# H616 register map
Vendor: Allwinner; Series: H616; File version: 0.1
CPU: other 0, little endian, MPU, no FPU, 0 interrupt priority bits
Registers are 32-bit, read-write, reset 0x0 unless marked. A register's access mark holds for its fields unless they carry their own. Offsets are from the block's base; [hi:lo] are bit positions; 'fields as' and 'values as' point back to an identical list; <NAME> marks a mode.

## SPI0
Base 0x05010000
Same registers: SPI1 0x05011000
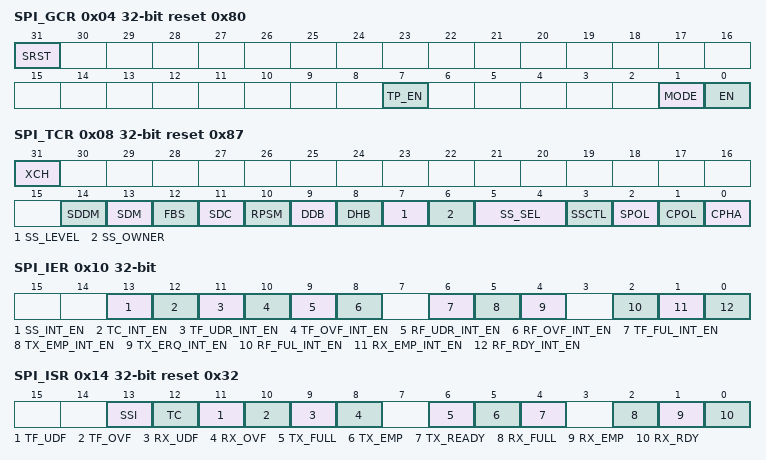
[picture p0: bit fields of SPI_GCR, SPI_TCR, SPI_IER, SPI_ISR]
0x04 SPI_GCR reset 0x80 — SPI Global Control Register
  [31] SRST — Soft reset Writing `1` to this bit will clear the SPI controller, and auto clear to `0` when reset operation completes. Writing `0` has no effect.
  [7] TP_EN — Transmit Pause Enable In master mode, it is used to control transmit state machine to stop smart burst sending when RX FIFO is full. 0: Normal operation, ignore RXFIFO status 1: Stop transmit data when RXFIFO full Cannot be written when XCH=1
    0=Normal operation, ignore RXFIFO status; 1=Stop transmit data when RXFIFO full Cannot be written when XCH=1
  [1] MODE — SPI Function Mode Select 0: Slave mode 1: Master mode Cannot be written when XCH=1
    0=Slave_mode; 1=Master mode Cannot be written when XCH=1
  [0] EN — SPI Module Enable Control 0: Disable 1: Enable After transforming from bit_mode to byte_mode, it must enable the SPI module again.
    0=Disable; 1=Enable After transforming from bit_mode to byte_mode, it must enable the SPI module again
0x08 SPI_TCR reset 0x87 — SPI Transfer Control Register
  [31] XCH — Exchange Burst In master mode it is used to start SPI burst 0: Idle 1: Initiates exchange. Writing `1` to this bit will start the SPI burst, and will auto clear after finishing the bursts transfer specified by BC. Writing `1` to SRST will also clear this bit. Writing `0` to this bit has no effect. Cannot be written when XCH=1.
    0=Idle; 1=Initiates exchange. Writing `1` to this bit will start the SPI burst, and will auto clear after finishing the bursts transfer specified by BC. Writing `1` to SRST will also clear this bit. Writing `0` to this bit has no effect. Cannot be written when XCH=1.
  [14] SDDM — Sending Data Delay Mode 0:Normal sending 1:Delay sending Set the bit to "1" to make the data that should be sent with a delay of half cycle of SPI_CLK in dual IO mode for SPI mode 0. Cannot be written when XCH=1.
  [13] SDM — Master Sample Data Mode 0: Delay sample mode 1: Normal sample mode In normal sample mode, SPI master samples the data at the correct edge for each SPI mode; In delay sample mode, SPI master samples data at the edge that is half cycle delayed by the correct edge defined in respective SPI mode. Cannot be written when XCH=1.
    0=Delay sample mode; 1=Normal sample mode In normal sample mode, SPI master samples the data at the correct edge for each SPI mode; In delay sample mode, SPI master samples data at the edge that is half cycle delayed by the correct edge defined in respective SPI mode. Cannot be written when XCH=1.
  [12] FBS — First Transmit Bit Select 0: MSB first 1: LSB first Cannot be written when XCH=1.
    0=MSB (MSB first); 1=LSB (LSB first Cannot be written when XCH=1.)
  [11] SDC — Master Sample Data Control Set this bit to `1` to make the internal read sample point with a delay of half cycle of SPI_CLK. It is used in high speed read operation to reduce the error caused by the time delay of SPI_CLK propagating between master and slave. 0: Normal operation, do not delay internal read sample point 1: Delay internal read sample point Cannot be written when XCH=1.
    0=Normal operation, do not delay internal read sample point; 1=Delay internal read sample point Cannot be written when XCH=1
  [10] RPSM — Rapids Mode Select Select rapid mode for high speed write. 0: Normal write mode 1: Rapid write mode Cannot be written when XCH=1.
    0=Normal write mode; 1=Rapid write mode Cannot be written when XCH=1
  [9] DDB — Dummy Burst Type 0: The bit value of dummy SPI burst is zero 1: The bit value of dummy SPI burst is one Cannot be written when XCH=1.
    0=zero (The bit value of dummy SPI burst is zero); 1=one (The bit value of dummy SPI burst is one Cannot be written when XCH=1.)
  [8] DHB — Discard Hash Burst In master mode it controls whether discarding unused SPI bursts 0: Receiving all SPI bursts in BC period 1: Discard unused SPI bursts, only fetching the SPI bursts during dummy burst period. The bursts number is specified by TC. Cannot be written when XCH=1.
    0=Receiving all SPI bursts in BC period; 1=Discard unused SPI bursts, only fetching the SPI bursts during dummy burst period. The bursts number is specified by TC. Cannot be written when XCH=1.
  [7] SS_LEVEL — When control SS signal manually (SPI_CTRL_REG.SS_CTRL==1), set this bit to `1` or `0` to control the level of SS signal. 0: set SS to low 1: set SS to high Cannot be written when XCH=1.
    0=set_SS_to_low; 1=set SS to high Cannot be written when XCH=1
  [6] SS_OWNER — SS Output Owner Select Usually, controller sends SS signal automatically with data together. When this bit is set to 1, software must manually write SPI_CTL_REG.SS_LEVEL to 1 or 0 to control the level of SS signal. 0: SPI controller 1: Software Cannot be written when XCH=1.
    0=SPI (SPI controller); 1=Software Cannot be written when XCH=1
  [5:4] SS_SEL — SPI Chip Select Select one of four external SPI Master/Slave Devices 00: SPI_SS0 will be asserted 01: SPI_SS1 will be asserted 10: SPI_SS2 will be asserted 11: SPI_SS3 will be asserted Cannot be written when XCH=1.
    0=SPI_SS0 (SPI_SS0 will be asserted); 1=SPI_SS1 (SPI_SS1 will be asserted); 2=SPI_SS2 (SPI_SS2 will be asserted); 3=SPI_SS3 (SPI_SS3 will be asserted Cannot be written when XCH=1.)
  [3] SSCTL — In master mode, this bit selects the output wave form for the SPI_SSx signal. Only valid when SS_OWNER = 0. 0: SPI_SSx remains asserted between SPI bursts 1: Negate SPI_SSx between SPI bursts Cannot be written when XCH=1.
    0=SPI_SSx remains asserted between SPI bursts; 1=Negate SPI_SSx between SPI bursts Cannot be written when XCH=1
  [2] SPOL — SPI Chip Select Signal Polarity Control 0: Active high polarity (0 = Idle) 1: Active low polarity (1 = Idle) Cannot be written when XCH=1.
    0=Active high polarity (0 = Idle); 1=Active low polarity (1 = Idle) Cannot be written when XCH=1
  [1] CPOL — SPI Clock Polarity Control 0: Active high polarity (0 = Idle) 1: Active low polarity (1 = Idle) Cannot be written when XCH=1.
    values as SPOL
  [0] CPHA — SPI Clock/Data Phase Control 0: Phase 0 (Leading edge for sample data) 1: Phase 1 (Leading edge for setup data) Cannot be written when XCH=1.
    0=Phase 0 (Leading edge for sample data); 1=Phase 1 (Leading edge for setup data) Cannot be written when XCH=1
0x10 SPI_IER — SPI Interrupt Control Register
  [all] fields
    0=Disable; 1=Enable
  [13] SS_INT_EN — SSI Interrupt Enable Chip select signal (SSx) from valid state to invalid state 0: Disable 1: Enable
  [12] TC_INT_EN — Transfer Completed Interrupt Enable 0: Disable 1: Enable
  [11] TF_UDR_INT_EN — TXFIFO Underrun Interrupt Enable 0: Disable 1: Enable
  [10] TF_OVF_INT_EN — TX FIFO Overflow Interrupt Enable 0: Disable 1: Enable
  [9] RF_UDR_INT_EN — RXFIFO Underrun Interrupt Enable 0: Disable 1: Enable
  [8] RF_OVF_INT_EN — RX FIFO Overflow Interrupt Enable 0: Disable 1: Enable
  [6] TF_FUL_INT_EN — TX FIFO Full Interrupt Enable 0: Disable 1: Enable
  [5] TX_EMP_INT_EN — TX FIFO Empty Interrupt Enable 0: Disable 1: Enable
  [4] TX_ERQ_INT_EN — TX FIFO Empty Request Interrupt Enable 0: Disable 1: Enable
  [2] RF_FUL_INT_EN — RX FIFO Full Interrupt Enable 0: Disable 1: Enable
  [1] RX_EMP_INT_EN — RX FIFO Empty Interrupt Enable 0: Disable 1: Enable
  [0] RF_RDY_INT_EN — RX FIFO Ready Request Interrupt Enable 0: Disable 1: Enable
0x14 SPI_ISR reset 0x32 — SPI Interrupt Status Register
  [13] SSI write-1-clears — SS Invalid Interrupt When SSI is 1, it indicates that SS has changed from valid state to invalid state. Writing 1 to this bit clears it.
  [12] TC write-1-clears — Transfer Completed In master mode, it indicates that all bursts specified by BC have been exchanged. In other condition, When set, this bit indicates that all the datas in TXFIFO have been loaded in the Shift register, and the Shift register has shifted out all the bits. Writing 1 to this bit clears it. 0: Busy 1: Transfer completed
    0=Busy; 1=Transfer completed
  [11] TF_UDF write-1-clears — TXFIFO Underrun This bit is set when if the TXFIFO is underrun. Writing 1 to this bit clears it. 0: TXFIFO is not underrun 1: TXFIFO is underrun
    0=not_underrun (TXFIFO is not underrun); 1=underrun (TXFIFO is underrun)
  [10] TF_OVF write-1-clears — TXFIFO Overflow This bit is set when if the TXFIFO is overflow. Writing 1 to this bit clears it. 0: TXFIFO is not overflow 1: TXFIFO is overflowed
    0=not_overflow (TXFIFO is not overflow); 1=overflowed (TXFIFO is overflowed)
  [9] RX_UDF write-1-clears — RXFIFO Underrun When set, this bit indicates that RXFIFO has underrun. Writing 1 to this bit clears it.
  [8] RX_OVF write-1-clears — RXFIFO Overflow When set, this bit indicates that RXFIFO has overflowed. Writing 1 to this bit clears it. 0: RXFIFO is available 1: RXFIFO is overflowed
    0=available (RXFIFO is available); 1=overflowed (RXFIFO is overflowed)
  [6] TX_FULL write-1-clears — TXFIFO Full This bit is set when if the TXFIFO is full . Writing 1 to this bit clears it. 0: TXFIFO is not Full 1: TXFIFO is Full
    0=not_Full (TXFIFO is not Full); 1=Full (TXFIFO is Full)
  [5] TX_EMP write-1-clears — TXFIFO Empty This bit is set if the TXFIFO is empty. Writing 1 to this bit clears it. 0: TXFIFO contains one or more words. 1: TXFIFO is empty
    0=TXFIFO contains one or more words; 1=empty (TXFIFO is empty)
  [4] TX_READY write-1-clears — TXFIFO Ready 0: TX_WL > TX_TRIG_LEVEL 1: TX_WL <= TX_TRIG_LEVEL This bit is set any time if TX_WL <= TX_TRIG_LEVEL. Writing `1` to this bit clears it. TX_WL is the water level of TXFIFO.
    0=TX_WL__gt_ (TX_WL > TX_TRIG_LEVEL); 1=TX_WL__lt__equals_ (TX_WL <= TX_TRIG_LEVEL This bit is set any time if TX_WL <= TX_TRIG_LEVEL. Writing `1` to this bit clears it. TX_WL is the water level of TXFIFO.)
  [2] RX_FULL write-1-clears — RXFIFO Full This bit is set when the RXFIFO is full . Writing 1 to this bit clears it. 0: Not Full 1: Full
    0=Not_Full; 1=Full
  [1] RX_EMP write-1-clears — RXFIFO Empty This bit is set when the RXFIFO is empty . Writing 1 to this bit clears it. 0: Not empty 1: empty
    0=Not_empty; 1=empty
  [0] RX_RDY write-1-clears — RXFIFO Ready 0: RX_WL < RX_TRIG_LEVEL 1: RX_WL >= RX_TRIG_LEVEL This bit is set any time if RX_WL >= RX_TRIG_LEVEL. Writing `1` to this bit clears it. RX_WL is the water level of RXFIFO.
    0=RX_WL__lt_ (RX_WL < RX_TRIG_LEVEL); 1=RX_WL__gt__equals_ (RX_WL >= RX_TRIG_LEVEL This bit is set any time if RX_WL >= RX_TRIG_LEVEL. Writing `1` to this bit clears it. RX_WL is the water level of RXFIFO.)
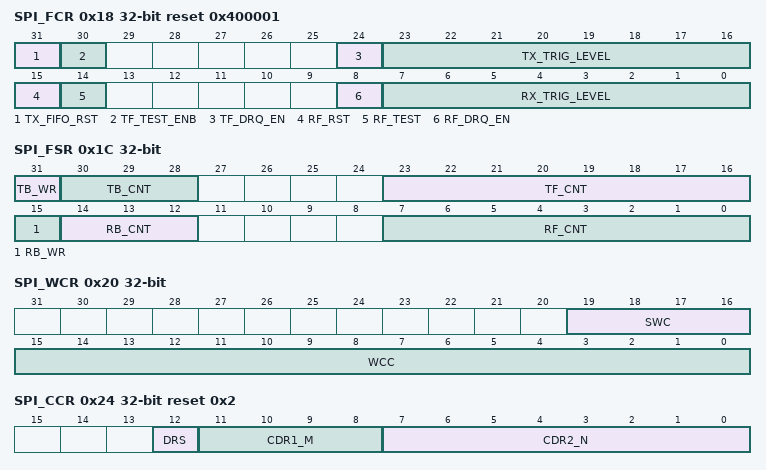
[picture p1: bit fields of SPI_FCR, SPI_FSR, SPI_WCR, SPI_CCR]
0x18 SPI_FCR reset 0x400001 — SPI FIFO Control Register
  [31] TX_FIFO_RST — TX FIFO Reset Writing `1` to this bit will reset the control portion of the TX FIFO and auto clear to `0` when completing reset operation, writing to `0` has no effect.
  [30] TF_TEST_ENB — TX Test Mode Enable 0: Disable 1: Enable Note: In normal mode, TX FIFO can only be read by SPI controller, writing `1` to this bit will switch TX FIFO read and write function to AHB bus. This bit is used to test the TX FIFO, donot set in normal operation and donot set RF_TEST and TF_TEST at the same time.
    0=Disable; 1=Enable Note: In normal mode, TX FIFO can only be read by SPI controller, writing `1` to this bit will switch TX FIFO read and write function to AHB bus. This bit is used to test the TX FIFO, donot set in normal operation and donot set RF_TEST and TF_TEST at the same time.
  [24] TF_DRQ_EN — TX FIFO DMA Request Enable 0: Disable 1: Enable
    0=Disable; 1=Enable
  [23:16] TX_TRIG_LEVEL — TX FIFO Empty Request Trigger Level
  [15] RF_RST — RXFIFO Reset Writing `1` to this bit will reset the control portion of the receiver FIFO, and auto clear to `0` when completing reset operation, writing `0` to this bit has no effect.
  [14] RF_TEST — RX Test Mode Enable 0: Disable 1: Enable Note: In normal mode, RX FIFO can only be written by SPI controller, writing `1` to this bit will switch RX FIFO read and write function to AHB bus. This bit is used to test the RX FIFO, donot set in normal operation and donot set RF_TEST and TF_TEST at the same time.
    0=Disable; 1=Enable Note: In normal mode, RX FIFO can only be written by SPI controller, writing `1` to this bit will switch RX FIFO read and write function to AHB bus. This bit is used to test the RX FIFO, donot set in normal operation and donot set RF_TEST and TF_TEST at the same time.
  [8] RF_DRQ_EN — RX FIFO DMA Request Enable 0: Disable 1: Enable
    0=Disable; 1=Enable
  [7:0] RX_TRIG_LEVEL — RX FIFO Ready Request Trigger Level
0x1C SPI_FSR — SPI FIFO Status Register
  [31] TB_WR ro — TX FIFO Write Buffer Write Enable
  [30:28] TB_CNT ro — TX FIFO Write Buffer Counter These bits indicate the number of words in TX FIFO Write Buffer
  [23:16] TF_CNT ro — TX FIFO Counter These bits indicate the number of words in TX FIFO 0: 0 byte in TX FIFO 1: 1 byte in TX FIFO ... 64: 64 bytes in TX FIFO other: Reserved
    64=64 bytes in TX FIFO other: Reserved
  [15] RB_WR ro — RX FIFO Read Buffer Write Enable
  [14:12] RB_CNT ro — RX FIFO Read Buffer Counter These bits indicate the number of words in RX FIFO Read Buffer
  [7:0] RF_CNT ro — RX FIFO Counter These bits indicate the number of words in RX FIFO 0: 0 byte in RX FIFO 1: 1 byte in RX FIFO ... 64: 64 bytes in RX FIFO other: Reserved
    64=64 bytes in RX FIFO other: Reserved
0x20 SPI_WCR — SPI Wait Clock Counter Register
  [19:16] SWC — Dual mode direction switch wait clock counter (for master mode only). Cannot be written when XCH=1. 0: No wait states inserted n: n SPI_SCLK wait states inserted Note: These bits control the number of wait states to be inserted before start dual data transfer in dual SPI mode. The SPI module counts SPI_SCLK by SWC for delaying next word data transfer.
  [15:0] WCC — Wait Clock Counter (In master mode) These bits control the number of wait states to be inserted in data transfers. The SPI module counts SPI_SCLK by WCC for delaying next word data transfer. 0: No wait states inserted N: N SPI_SCLK wait states inserted
0x24 SPI_CCR reset 0x2 — SPI Clock Rate Control Register
  [12] DRS — Divide Rate Select (Master Mode Only) 0: Select Clock Divide Rate 1 1: Select Clock Divide Rate 2 Cannot be written when XCH=1.
    0=Select_Clock_Divide_Rate_1; 1=Select Clock Divide Rate 2 Cannot be written when XCH=1
  [11:8] CDR1_M — Clock Divide Rate 1 (Master Mode Only) The SPI_SCLK is determined according to the following equation: SPI_CLK = Source_CLK / (2^CDR1_M). Cannot be written when XCH=1.
  [7:0] CDR2_N — Clock Divide Rate 2 (Master Mode Only) The SPI_SCLK is determined according to the following equation: SPI_CLK = Source_CLK / (2*(CDR2_N + 1)). Cannot be written when XCH=1.
0x30 SPI_MBC — SPI Burst Counter Register
  [23:0] MBC — Master Burst Counter In master mode, this field specifies the total burst number. 0: 0 burst 1: 1 burst ... N: N bursts Cannot be written when XCH=1. Note: Total transfer data, includes the TXD, RXD and dummy burst.
0x34 SPI_MTC — SPI Transmit Counter Register
  [23:0] MWTC — Master Write Transmit Counter In master mode, this field specifies the burst number that should be sent to TXFIFO before automatically sending dummy burst. For saving bus bandwidth, the dummy burst (all zero bits or all one bits) is sent by SPI Controller automatically. 0: 0 burst 1: 1 burst ... N: N bursts Can`t be written when XCH=1.
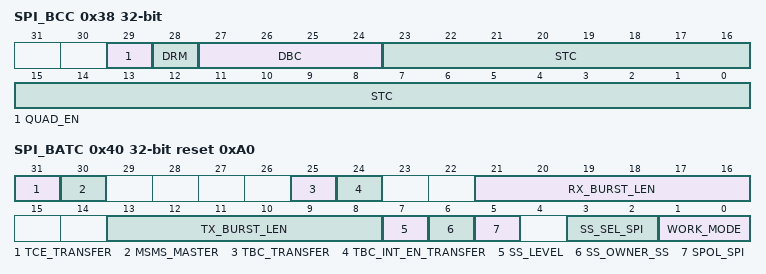
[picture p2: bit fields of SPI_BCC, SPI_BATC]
0x38 SPI_BCC — SPI Burst Control Register
  [29] QUAD_EN — Quad_Mode_EN 0: Quad mode disable 1: Quad mode enable Cannot be written when XCH=1. Note: Quad mode includes Quad-Input and Quad-Output.
    0=disable (Quad mode disable); 1=enable (Quad mode enable Cannot be written when XCH=1. Note: Quad mode includes Quad-Input and Quad-Output.)
  [28] DRM — Master Dual Mode RX Enable 0: RX use single-bit mode 1: RX use dual mode Cannot be written when XCH=1. It is only valid when Quad_Mode_EN=0.
    0=RX use single-bit mode; 1=RX use dual mode Cannot be written when XCH=1. It is only valid when Quad_Mode_EN=0.
  [27:24] DBC — Master Dummy Burst Counter In master mode, this field specifies the burst number that should be sent before receive in dual SPI mode. The data does not care by the device. 0: 0 burst 1: 1 burst ... N: N bursts Cannot be written when XCH=1.
  [23:0] STC — Master Single Mode Transmit Counter In master mode, this field specifies the burst number that should be sent in single mode before automatically sending dummy burst. This is the first transmit counter in all bursts. 0: 0 burst 1: 1 burst ... N: N bursts Cannot be written when XCH=1.
0x40 SPI_BATC reset 0xA0
  [31] TCE_TRANSFER — TCE Transfer Control Enable In master mode, it is used to start to transfer the serial bits frame, it is only valid when Work Mode Select==0x10/0x11. 0: Idle 1: Initiates transfer Writing `1` to this bit will start to transfer serial bits frame(the value comes from the SPI TX Bit Register or SPI RX Bit Register ), and will auto clear after the bursts transfer completely. Writing `0` to this bit has no effect.
    0=Idle; 1=Initiates transfer Writing `1` to this bit will start to transfer serial bits frame(the value comes from the SPI TX Bit Register or SPI RX Bit Register ), and will auto clear after the bursts transfer completely. Writing `0` to this bit has no effect.
  [30] MSMS_MASTER — MSMS Master Sample Standard 0: Delay Sample Mode 1: Standard Sample Mode In Standard Sample Mode, SPI master samples the data at the standard rising edge of SCLK for each SPI mode; In Delay Sample Mode, SPI master samples data at the edge that is half cycle delayed by the standard rising edge of SCLK defined in respective SPI mode.
    0=Delay Sample Mode; 1=Standard Sample Mode In Standard Sample Mode, SPI master samples the data at the standard rising edge of SCLK for each SPI mode; In Delay Sample Mode, SPI master samples data at the edge that is half cycle delayed by the standard rising edge of SCLK defined in respective SPI mode
  [25] TBC_TRANSFER write-1-clears — TBC Transfer Bits Completed When set, this bit indicates that the last bit of the serial data frame in SPI TX Bit Register SPI RX Bit Register has been transferred completely. Writing 1 to this bit clears it. 0: Busy 1: Transfer Completed It is only valid when Work Mode Select==0x10/0x11.
    0=Busy; 1=Transfer Completed It is only valid when Work Mode Select==0x10/0x11
  [24] TBC_INT_EN_TRANSFER — TBC_INT_EN Transfer Bits Completed Interrupt Enable 0: Disable 1: Enable It is only valid when Work Mode Select==0x10/0x11.
    0=Disable; 1=Enable It is only valid when Work Mode Select==0x10/0x11
  [21:16] RX_BURST_LEN — Configure the length of serial data frame(burst) of RX 000000: 0bit 000001: 1bit ... 100000: 32bits Other values: reserved It is only valid when Work Mode Select==0x10/0x11, and cannot be written when TCE=1.
    0=_0bit; 1=_1bit; 32=32bits Other values: reserved It is only valid when Work Mode Select==0x10/0x11, and cannot be written when TCE=1
  [13:8] TX_BURST_LEN — Configure the length of serial data frame(burst) of TX 000000: 0bit 000001: 1bit ... 100000: 32bits Other values: reserved It is only valid when Work Mode Select==0x10/0x11, and cannot be written when TCE=1.
    values as RX_BURST_LEN
  [7] SS_LEVEL — SS_LEVEL When control SS signal manually , set this bit to `1` or `0` to control the level of SS signal. 0: Set SS to low 1: Set SS to high It is only valid when Work Mode Select==0x10/0x11, and only work in Mode0 , cannot be written when TCE=1.
    0=Set_SS_to_low; 1=Set SS to high It is only valid when Work Mode Select==0x10/0x11, and only work in Mode0 , cannot be written when TCE=1
  [6] SS_OWNER_SS — SS_OWNER SS Output Owner Select Usually, controller sends SS signal automatically with data together. When this bit is set to 1, software must manually write SPI_CTL_REG.SS_LEVEL to 1 or 0 to control the level of SS signal. 0: SPI controller 1: Software It is only valid when Work Mode Select==0x10/0x11, and only work in Mode0 , cannot be written when TCE=1.
    0=SPI (SPI controller); 1=Software It is only valid when Work Mode Select==0x10/0x11, and only work in Mode0 , cannot be written when TCE=1
  [5] SPOL_SPI — SPOL SPI Chip Select Signal Polarity Control 0: Active high polarity (0 = Idle) 1: Active low polarity (1 = Idle) It is only valid when Work Mode Select==0x10/0x11, and only work in Mode0 , cannot be written when TCE=1.
    0=Active high polarity (0 = Idle); 1=Active low polarity (1 = Idle) It is only valid when Work Mode Select==0x10/0x11, and only work in Mode0 , cannot be written when TCE=1
  [3:2] SS_SEL_SPI — SS_SEL SPI Chip Select Select one of four external SPI Master/Slave Devices 00: SPI_SS0 will be asserted 01: SPI_SS1 will be asserted 10: SPI_SS2 will be asserted 11: SPI_SS3 will be asserted It is only valid when Work Mode Select= =0x10/0x11, and only work in Mode0 , cannot be written when TCE=1.
    0=SPI_SS0 (SPI_SS0 will be asserted); 1=SPI_SS1 (SPI_SS1 will be asserted); 2=SPI_SS2 (SPI_SS2 will be asserted); 3=SPI_SS3 (SPI_SS3 will be asserted It is only valid when Work Mode Select= =0x10/0x11, and only work in Mode0 , cannot be written when TCE=1.)
  [1:0] WORK_MODE — Work Mode Select 00: Data frame is byte aligned in standard SPI, dual-output/dual input SPI, dual IO SPI and quad-output/quad-input SPI. 01: Reserved 10: Data frame is bit aligned in 3-wire SPI 11: Data frame is bit aligned in standard SPI
    0=byte_aligned_in_standard (Data frame is byte aligned in standard SPI, dual-output/dual input SPI, dual IO SPI and quad-output/quad-input SPI.); 2=bit_aligned_in_3_wire (Data frame is bit aligned in 3-wire SPI); 3=bit_aligned_in_standard (Data frame is bit aligned in standard SPI)
0x44 SPI_BA_CCR
  [7:0] CDR_N — Clock Divide Rate (Master Mode Only) The SPI_SCLK is determined according to the following equation: SPI_CLK = Source_CLK / (2*(CDR_N + 1)).
0x48 SPI_TBR — SPI TX Bit Register
  [31:0] VTB — The Value of the Transmit Bits This register is used to store the value of the transmitted serial data frame. In the process of transmission, the LSB is transmitted first.
0x4C SPI_RBR — SPI RX Bit Register
  [31:0] VRB — The Value of the Receive Bits This register is used to store the value of the received serial data frame. In the process of transmission, the LSB is transmitted first.
0x88 SPI_NDMA_MODE_CTL reset 0xE5 — SPI Normal DMA Mode Control Register
  [4:0] DELAY_CYCLES_THE_COUNTS_OF_HOLD — Delay Cycles The counts of hold cycles from DMA last signal high to dma_active high
0x200 SPI_TXD — SPI TX Data Register
  [31:0] TDATA — Transmit Data This register can be accessed in byte, half-word or word unit by AHB. In byte accessing method, if there are rooms in TXFIFO, one burst data is written to TXFIFO and the depth is increased by 1. In half-word accessing method, two SPI burst data are written and the TXFIFO depth is increased by 2. In word accessing method, four SPI burst data are written and the TXFIFO depth is increased by 4. Note: This address is writable-only if TF_TEST is `0`, and if TF_TEST is set to `1`, this address is readable and writable to test the TX FIFO through the AHB bus.
0x300 SPI_RXD — SPI RX Data Register
  [31:0] RDATA ro — Receive Data This register can be accessed in byte, half-word or word unit by AHB. In byte accessing method, if there are data in RXFIFO, the top word is returned and the RXFIFO depth is decreased by 1. In half-word accessing method, two SPI bursts are returned and the RXFIFO depth is decreased by 2. In word accessing method, the four SPI bursts are returned and the RXFIFO depth is decreased by 4. Note: This address is readable-only if RF_TEST is `0`, and if RF_TEST is set to `1`, this address is readable and writable to test the RX FIFO through the AHB bus.
